VERSION ""

NS_ :

BS_:

BU_: AMS VCU ECU UDV Pit_Tool

BA_DEF_ BO_  "GenMsgCycleTime" INT 0 65535;
BA_DEF_DEF_  "GenMsgCycleTime" 0;

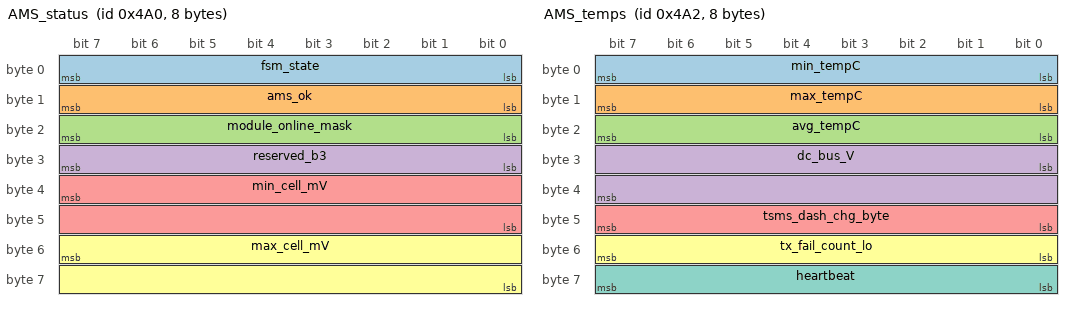
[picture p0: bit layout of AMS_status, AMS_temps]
BO_ 1184 AMS_status: 8 AMS
 SG_ fsm_state : 0|8@1+ (1,0) [0|0] "enum" Vector__XXX
 SG_ ams_ok : 8|8@1+ (1,0) [0|0] "bool" Vector__XXX
 SG_ module_online_mask : 16|8@1+ (1,0) [0|0] "bitmask" Vector__XXX
 SG_ reserved_b3 : 24|8@1+ (1,0) [0|0] "" Vector__XXX
 SG_ min_cell_mV : 39|16@0+ (1,0) [0|0] "mV" Vector__XXX
 SG_ max_cell_mV : 55|16@0+ (1,0) [0|0] "mV" Vector__XXX

BO_ 1185 AMS_pack: 8 AMS
 SG_ pack_voltage_mV : 0|32@1+ (1,0) [0|0] "mV" Vector__XXX
 SG_ filtered_mA : 32|32@1- (1,0) [0|0] "mA" Vector__XXX

BO_ 1186 AMS_temps: 8 AMS
 SG_ min_tempC : 0|8@1- (1,0) [0|0] "degC" Vector__XXX
 SG_ max_tempC : 8|8@1- (1,0) [0|0] "degC" Vector__XXX
 SG_ avg_tempC : 16|8@1- (1,0) [0|0] "degC" Vector__XXX
 SG_ dc_bus_V : 24|16@1+ (1,0) [0|0] "V" Vector__XXX
 SG_ tsms_dash_chg_byte : 40|8@1+ (1,0) [0|0] "bitfield" Vector__XXX
 SG_ tx_fail_count_lo : 48|8@1+ (1,0) [0|0] "" Vector__XXX
 SG_ heartbeat : 56|8@1+ (1,0) [0|0] "" Vector__XXX

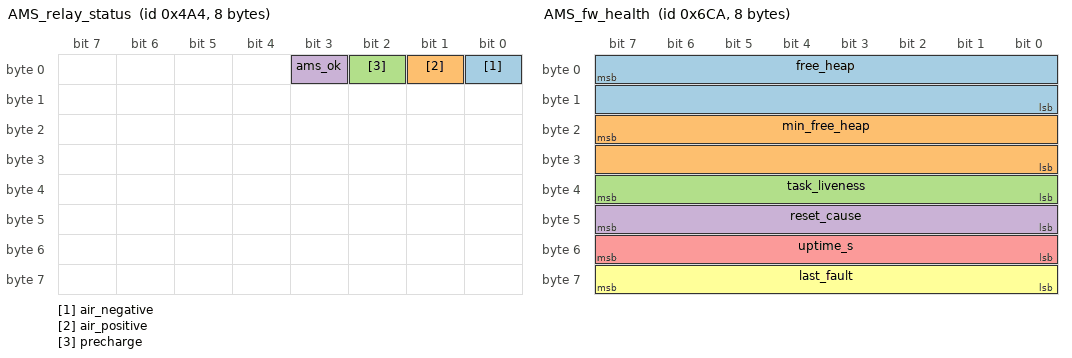
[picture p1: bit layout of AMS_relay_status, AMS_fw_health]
BO_ 1188 AMS_relay_status: 8 AMS
 SG_ air_negative : 0|1@1+ (1,0) [0|0] "bool" Vector__XXX
 SG_ air_positive : 1|1@1+ (1,0) [0|0] "bool" Vector__XXX
 SG_ precharge : 2|1@1+ (1,0) [0|0] "bool" Vector__XXX
 SG_ ams_ok : 3|1@1+ (1,0) [0|0] "bool" Vector__XXX

BO_ 1738 AMS_fw_health: 8 AMS
 SG_ free_heap : 7|16@0+ (1,0) [0|0] "bytes" Vector__XXX
 SG_ min_free_heap : 23|16@0+ (1,0) [0|0] "bytes" Vector__XXX
 SG_ task_liveness : 32|8@1+ (1,0) [0|0] "bitfield" Vector__XXX
 SG_ reset_cause : 40|8@1+ (1,0) [0|0] "enum" Vector__XXX
 SG_ uptime_s : 48|8@1+ (1,0) [0|0] "seconds" Vector__XXX
 SG_ last_fault : 56|8@1+ (1,0) [0|0] "sentinel" Vector__XXX

BO_ 32 ACU_ok_precharge: 1 AMS
 SG_ ok_precharge : 0|8@1+ (1,0) [0|0] "bool" Vector__XXX

BO_ 33 ACU_discharge_interlock: 1 AMS
 SG_ fsm_in_start : 0|1@1+ (1,0) [0|0] "bool" Vector__XXX
 SG_ tsms : 1|1@1+ (1,0) [0|0] "bool" Vector__XXX

BO_ 300 ACU_v_cell_min: 2 AMS
 SG_ min_cell_mV : 7|16@0+ (1,0) [0|0] "mV" Vector__XXX

BO_ 305 ACU_vmin_module_a: 6 AMS
 SG_ vmin_module0 : 7|16@0+ (1,0) [0|0] "mV" Vector__XXX
 SG_ vmin_module1 : 23|16@0+ (1,0) [0|0] "mV" Vector__XXX
 SG_ vmin_module2 : 39|16@0+ (1,0) [0|0] "mV" Vector__XXX

BO_ 306 ACU_vmin_module_b: 4 AMS
 SG_ vmin_module3 : 7|16@0+ (1,0) [0|0] "mV" Vector__XXX
 SG_ vmin_module4 : 23|16@0+ (1,0) [0|0] "mV" Vector__XXX

BO_ 307 ACU_vmax_module_a: 6 AMS
 SG_ vmax_module0 : 7|16@0+ (1,0) [0|0] "mV" Vector__XXX
 SG_ vmax_module1 : 23|16@0+ (1,0) [0|0] "mV" Vector__XXX
 SG_ vmax_module2 : 39|16@0+ (1,0) [0|0] "mV" Vector__XXX

BO_ 308 ACU_vmax_module_b: 4 AMS
 SG_ vmax_module3 : 7|16@0+ (1,0) [0|0] "mV" Vector__XXX
 SG_ vmax_module4 : 23|16@0+ (1,0) [0|0] "mV" Vector__XXX

BO_ 309 ACU_currents: 4 AMS
 SG_ current_accu_dA : 7|16@0- (0.1,0) [0|0] "A" Vector__XXX
 SG_ current_dcdc_dA : 23|16@0- (0.1,0) [0|0] "A" Vector__XXX

BO_ 310 ACU_tmax_module_a: 6 AMS
 SG_ tmax_module0 : 7|16@0- (1,0) [0|0] "degC" Vector__XXX
 SG_ tmax_module1 : 23|16@0- (1,0) [0|0] "degC" Vector__XXX
 SG_ tmax_module2 : 39|16@0- (1,0) [0|0] "degC" Vector__XXX

BO_ 311 ACU_tmax_module_b: 6 AMS
 SG_ tmax_module3 : 7|16@0- (1,0) [0|0] "degC" Vector__XXX
 SG_ tmax_module4 : 23|16@0- (1,0) [0|0] "degC" Vector__XXX
 SG_ tmax_dcdc : 39|16@0- (1,0) [0|0] "degC" Vector__XXX

BO_ 304 ACU_soc: 1 AMS
 SG_ soc_percent : 7|8@0+ (1,0) [0|0] "%" Vector__XXX

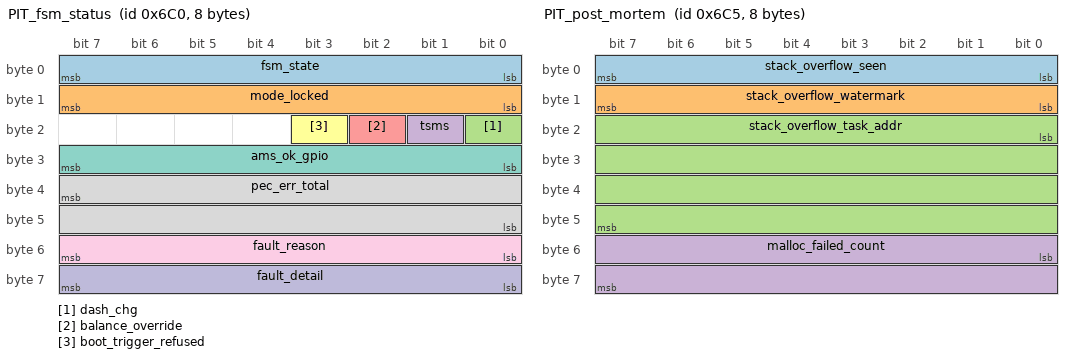
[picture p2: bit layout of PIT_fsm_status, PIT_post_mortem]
BO_ 1728 PIT_fsm_status: 8 AMS
 SG_ fsm_state : 0|8@1+ (1,0) [0|0] "enum" Vector__XXX
 SG_ mode_locked : 8|8@1+ (1,0) [0|0] "enum" Vector__XXX
 SG_ dash_chg : 16|1@1+ (1,0) [0|0] "bool" Vector__XXX
 SG_ tsms : 17|1@1+ (1,0) [0|0] "bool" Vector__XXX
 SG_ balance_override : 18|1@1+ (1,0) [0|0] "bool" Vector__XXX
 SG_ boot_trigger_refused : 19|1@1+ (1,0) [0|0] "bool" Vector__XXX
 SG_ ams_ok_gpio : 24|8@1+ (1,0) [0|0] "bool" Vector__XXX
 SG_ pec_err_total : 39|16@0+ (1,0) [0|0] "count" Vector__XXX
 SG_ fault_reason : 48|8@1+ (1,0) [0|0] "enum" Vector__XXX
 SG_ fault_detail : 56|8@1+ (1,0) [0|0] "" Vector__XXX

BO_ 1729 PIT_timing: 8 AMS
 SG_ bms_volt_poll_ms : 7|16@0+ (1,0) [0|0] "ms" Vector__XXX
 SG_ bms_volt_poll_max_ms : 23|16@0+ (1,0) [0|0] "ms" Vector__XXX
 SG_ temp_sweep_last_mask : 32|32@1+ (1,0) [0|0] "bitmask" Vector__XXX

BO_ 1730 PIT_balance_mask_a: 8 AMS
 SG_ dcc_mask_lo : 0|64@1+ (1,0) [0|0] "bitmask" Vector__XXX

BO_ 1731 PIT_balance_mask_b: 8 AMS
 SG_ dcc_mask_hi : 0|32@1+ (1,0) [0|0] "bitmask" Vector__XXX
 SG_ cycles_total : 32|16@1+ (1,0) [0|0] "count" Vector__XXX
 SG_ cycles_active : 48|16@1+ (1,0) [0|0] "count" Vector__XXX

BO_ 1732 PIT_boot_diag: 8 AMS
 SG_ jump_reason : 0|32@1+ (1,0) [0|0] "enum" Vector__XXX
 SG_ app_init_progress : 32|8@1+ (1,0) [0|0] "count" Vector__XXX
 SG_ fdcan1_start_result : 40|24@1+ (1,0) [0|0] "status" Vector__XXX

BO_ 1733 PIT_post_mortem: 8 AMS
 SG_ stack_overflow_seen : 0|8@1+ (1,0) [0|0] "bool" Vector__XXX
 SG_ stack_overflow_watermark : 8|8@1+ (1,0) [0|0] "" Vector__XXX
 SG_ stack_overflow_task_addr : 16|32@1+ (1,0) [0|0] "" Vector__XXX
 SG_ malloc_failed_count : 48|16@1+ (1,0) [0|0] "count" Vector__XXX

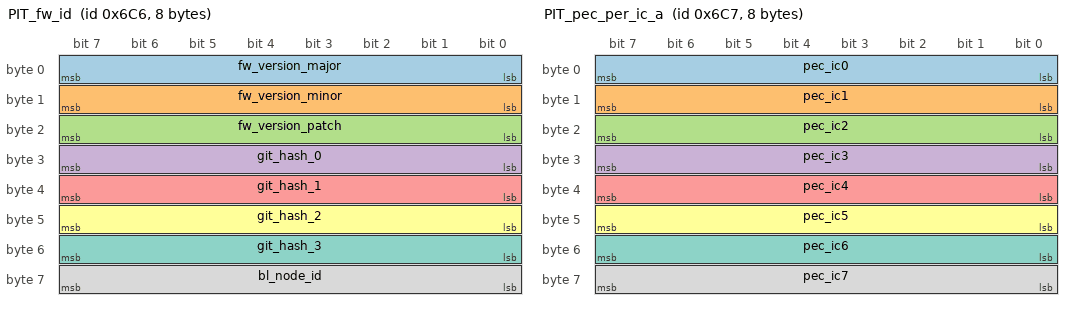
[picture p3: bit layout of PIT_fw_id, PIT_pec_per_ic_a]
BO_ 1734 PIT_fw_id: 8 AMS
 SG_ fw_version_major : 0|8@1+ (1,0) [0|0] "" Vector__XXX
 SG_ fw_version_minor : 8|8@1+ (1,0) [0|0] "" Vector__XXX
 SG_ fw_version_patch : 16|8@1+ (1,0) [0|0] "" Vector__XXX
 SG_ git_hash_0 : 24|8@1+ (1,0) [0|0] "" Vector__XXX
 SG_ git_hash_1 : 32|8@1+ (1,0) [0|0] "" Vector__XXX
 SG_ git_hash_2 : 40|8@1+ (1,0) [0|0] "" Vector__XXX
 SG_ git_hash_3 : 48|8@1+ (1,0) [0|0] "" Vector__XXX
 SG_ bl_node_id : 56|8@1+ (1,0) [0|0] "" Vector__XXX

BO_ 1735 PIT_pec_per_ic_a: 8 AMS
 SG_ pec_ic0 : 0|8@1+ (1,0) [0|0] "count" Vector__XXX
 SG_ pec_ic1 : 8|8@1+ (1,0) [0|0] "count" Vector__XXX
 SG_ pec_ic2 : 16|8@1+ (1,0) [0|0] "count" Vector__XXX
 SG_ pec_ic3 : 24|8@1+ (1,0) [0|0] "count" Vector__XXX
 SG_ pec_ic4 : 32|8@1+ (1,0) [0|0] "count" Vector__XXX
 SG_ pec_ic5 : 40|8@1+ (1,0) [0|0] "count" Vector__XXX
 SG_ pec_ic6 : 48|8@1+ (1,0) [0|0] "count" Vector__XXX
 SG_ pec_ic7 : 56|8@1+ (1,0) [0|0] "count" Vector__XXX

BO_ 1736 PIT_pec_per_ic_b: 8 AMS
 SG_ pec_ic8 : 0|8@1+ (1,0) [0|0] "count" Vector__XXX
 SG_ pec_ic9 : 8|8@1+ (1,0) [0|0] "count" Vector__XXX

BO_ 1737 PIT_comms_health: 8 AMS
 SG_ fdcan1_busoff_recovery_count : 0|32@1+ (1,0) [0|0] "count" Vector__XXX
 SG_ acu_tx_fail : 32|32@1+ (1,0) [0|0] "count" Vector__XXX

BO_ 1739 PIT_balance_health: 8 AMS
 SG_ balance_quiesce_ok : 0|32@1+ (1,0) [0|0] "count" Vector__XXX
 SG_ balance_quiesce_fail : 32|32@1+ (1,0) [0|0] "count" Vector__XXX

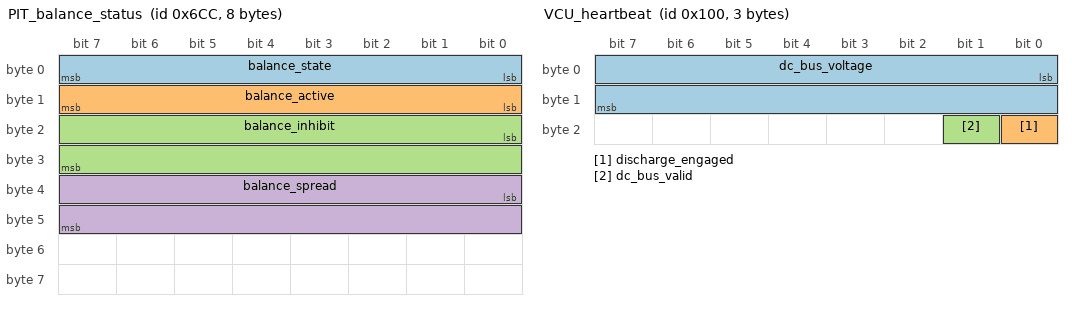
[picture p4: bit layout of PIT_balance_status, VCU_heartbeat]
BO_ 1740 PIT_balance_status: 8 AMS
 SG_ balance_state : 0|8@1+ (1,0) [0|0] "enum" Vector__XXX
 SG_ balance_active : 8|8@1+ (1,0) [0|0] "count" Vector__XXX
 SG_ balance_inhibit : 16|16@1+ (1,0) [0|0] "bitmask" Vector__XXX
 SG_ balance_spread : 32|16@1+ (1,0) [0|0] "mV" Vector__XXX

BO_ 2033 PitDiag_ack: 1 AMS
 SG_ enabled : 0|8@1+ (1,0) [0|0] "bool" Vector__XXX

BO_ 256 VCU_heartbeat: 3 VCU
 SG_ dc_bus_voltage : 0|16@1+ (1,0) [0|0] "V" Vector__XXX
 SG_ discharge_engaged : 16|1@1+ (1,0) [0|0] "bool" Vector__XXX
 SG_ dc_bus_valid : 17|1@1+ (1,0) [0|0] "bool" Vector__XXX

BO_ 257 Operator_charge_request: 4 Pit_Tool
 SG_ magic : 7|32@0+ (1,0) [0|0] "magic" Vector__XXX

BO_ 259 Operator_balance_override: 4 Pit_Tool
 SG_ magic : 7|32@0+ (1,0) [0|0] "magic" Vector__XXX

BO_ 260 Operator_balance_modules: 5 Pit_Tool
 SG_ magic : 7|32@0+ (1,0) [0|0] "magic" Vector__XXX
 SG_ module_enable : 32|5@1+ (1,0) [0|0] "bitmask" Vector__XXX

BO_ 2032 PitDiag_cmd: 4 Pit_Tool
 SG_ cmd_magic : 7|32@0+ (1,0) [0|0] "magic" Vector__XXX

BO_ 2 BL_boot_trigger: 4 Pit_Tool
 SG_ magic : 7|32@0+ (1,0) [0|0] "magic" Vector__XXX

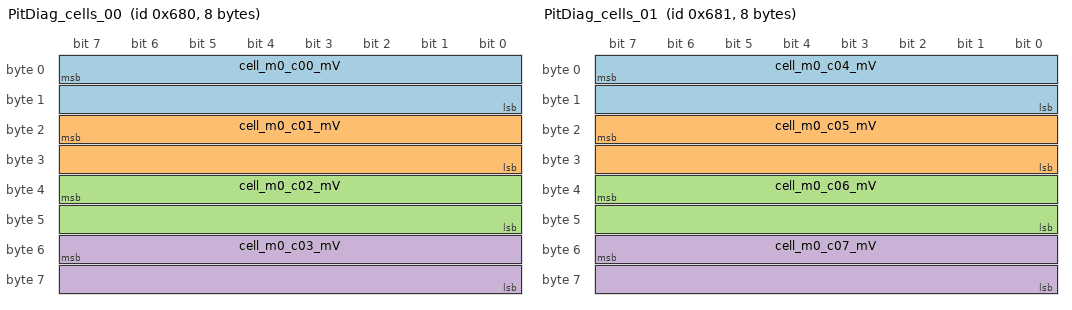
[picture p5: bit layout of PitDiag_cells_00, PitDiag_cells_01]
BO_ 1664 PitDiag_cells_00: 8 AMS
 SG_ cell_m0_c00_mV : 7|16@0+ (1,0) [0|5000] "mV" Vector__XXX
 SG_ cell_m0_c01_mV : 23|16@0+ (1,0) [0|5000] "mV" Vector__XXX
 SG_ cell_m0_c02_mV : 39|16@0+ (1,0) [0|5000] "mV" Vector__XXX
 SG_ cell_m0_c03_mV : 55|16@0+ (1,0) [0|5000] "mV" Vector__XXX

BO_ 1665 PitDiag_cells_01: 8 AMS
 SG_ cell_m0_c04_mV : 7|16@0+ (1,0) [0|5000] "mV" Vector__XXX
 SG_ cell_m0_c05_mV : 23|16@0+ (1,0) [0|5000] "mV" Vector__XXX
 SG_ cell_m0_c06_mV : 39|16@0+ (1,0) [0|5000] "mV" Vector__XXX
 SG_ cell_m0_c07_mV : 55|16@0+ (1,0) [0|5000] "mV" Vector__XXX

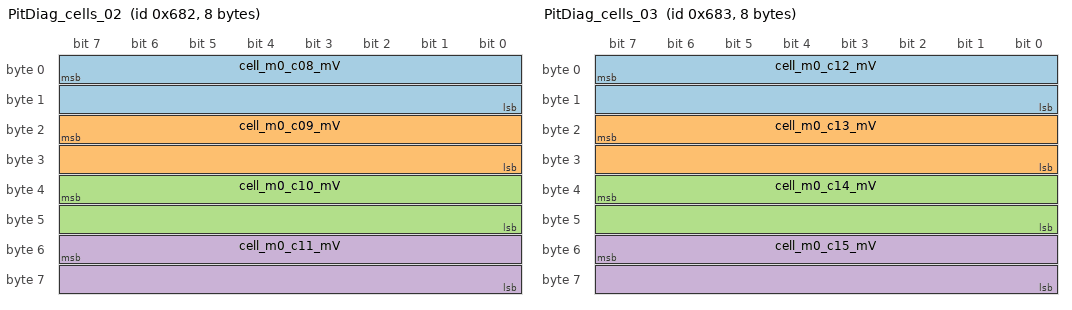
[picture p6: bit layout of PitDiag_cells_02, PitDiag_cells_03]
BO_ 1666 PitDiag_cells_02: 8 AMS
 SG_ cell_m0_c08_mV : 7|16@0+ (1,0) [0|5000] "mV" Vector__XXX
 SG_ cell_m0_c09_mV : 23|16@0+ (1,0) [0|5000] "mV" Vector__XXX
 SG_ cell_m0_c10_mV : 39|16@0+ (1,0) [0|5000] "mV" Vector__XXX
 SG_ cell_m0_c11_mV : 55|16@0+ (1,0) [0|5000] "mV" Vector__XXX

BO_ 1667 PitDiag_cells_03: 8 AMS
 SG_ cell_m0_c12_mV : 7|16@0+ (1,0) [0|5000] "mV" Vector__XXX
 SG_ cell_m0_c13_mV : 23|16@0+ (1,0) [0|5000] "mV" Vector__XXX
 SG_ cell_m0_c14_mV : 39|16@0+ (1,0) [0|5000] "mV" Vector__XXX
 SG_ cell_m0_c15_mV : 55|16@0+ (1,0) [0|5000] "mV" Vector__XXX

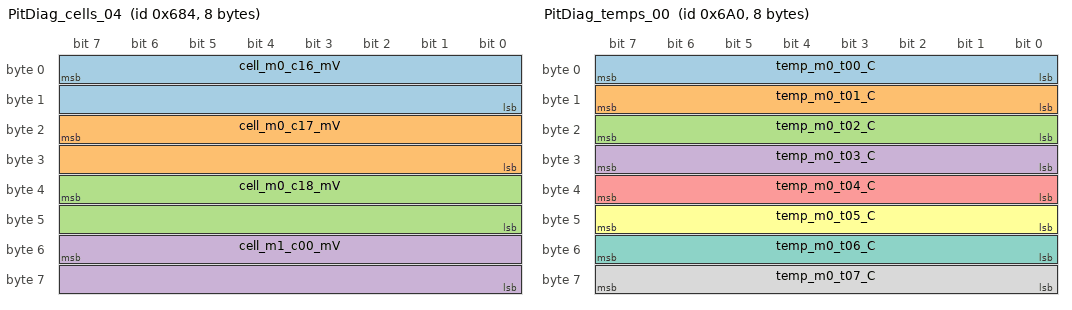
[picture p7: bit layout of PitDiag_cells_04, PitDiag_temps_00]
BO_ 1668 PitDiag_cells_04: 8 AMS
 SG_ cell_m0_c16_mV : 7|16@0+ (1,0) [0|5000] "mV" Vector__XXX
 SG_ cell_m0_c17_mV : 23|16@0+ (1,0) [0|5000] "mV" Vector__XXX
 SG_ cell_m0_c18_mV : 39|16@0+ (1,0) [0|5000] "mV" Vector__XXX
 SG_ cell_m1_c00_mV : 55|16@0+ (1,0) [0|5000] "mV" Vector__XXX

BO_ 1669 PitDiag_cells_05: 8 AMS
 SG_ cell_m1_c01_mV : 7|16@0+ (1,0) [0|5000] "mV" Vector__XXX
 SG_ cell_m1_c02_mV : 23|16@0+ (1,0) [0|5000] "mV" Vector__XXX
 SG_ cell_m1_c03_mV : 39|16@0+ (1,0) [0|5000] "mV" Vector__XXX
 SG_ cell_m1_c04_mV : 55|16@0+ (1,0) [0|5000] "mV" Vector__XXX

BO_ 1670 PitDiag_cells_06: 8 AMS
 SG_ cell_m1_c05_mV : 7|16@0+ (1,0) [0|5000] "mV" Vector__XXX
 SG_ cell_m1_c06_mV : 23|16@0+ (1,0) [0|5000] "mV" Vector__XXX
 SG_ cell_m1_c07_mV : 39|16@0+ (1,0) [0|5000] "mV" Vector__XXX
 SG_ cell_m1_c08_mV : 55|16@0+ (1,0) [0|5000] "mV" Vector__XXX

BO_ 1671 PitDiag_cells_07: 8 AMS
 SG_ cell_m1_c09_mV : 7|16@0+ (1,0) [0|5000] "mV" Vector__XXX
 SG_ cell_m1_c10_mV : 23|16@0+ (1,0) [0|5000] "mV" Vector__XXX
 SG_ cell_m1_c11_mV : 39|16@0+ (1,0) [0|5000] "mV" Vector__XXX
 SG_ cell_m1_c12_mV : 55|16@0+ (1,0) [0|5000] "mV" Vector__XXX

BO_ 1672 PitDiag_cells_08: 8 AMS
 SG_ cell_m1_c13_mV : 7|16@0+ (1,0) [0|5000] "mV" Vector__XXX
 SG_ cell_m1_c14_mV : 23|16@0+ (1,0) [0|5000] "mV" Vector__XXX
 SG_ cell_m1_c15_mV : 39|16@0+ (1,0) [0|5000] "mV" Vector__XXX
 SG_ cell_m1_c16_mV : 55|16@0+ (1,0) [0|5000] "mV" Vector__XXX

BO_ 1673 PitDiag_cells_09: 8 AMS
 SG_ cell_m1_c17_mV : 7|16@0+ (1,0) [0|5000] "mV" Vector__XXX
 SG_ cell_m1_c18_mV : 23|16@0+ (1,0) [0|5000] "mV" Vector__XXX
 SG_ cell_m2_c00_mV : 39|16@0+ (1,0) [0|5000] "mV" Vector__XXX
 SG_ cell_m2_c01_mV : 55|16@0+ (1,0) [0|5000] "mV" Vector__XXX

BO_ 1674 PitDiag_cells_10: 8 AMS
 SG_ cell_m2_c02_mV : 7|16@0+ (1,0) [0|5000] "mV" Vector__XXX
 SG_ cell_m2_c03_mV : 23|16@0+ (1,0) [0|5000] "mV" Vector__XXX
 SG_ cell_m2_c04_mV : 39|16@0+ (1,0) [0|5000] "mV" Vector__XXX
 SG_ cell_m2_c05_mV : 55|16@0+ (1,0) [0|5000] "mV" Vector__XXX

BO_ 1675 PitDiag_cells_11: 8 AMS
 SG_ cell_m2_c06_mV : 7|16@0+ (1,0) [0|5000] "mV" Vector__XXX
 SG_ cell_m2_c07_mV : 23|16@0+ (1,0) [0|5000] "mV" Vector__XXX
 SG_ cell_m2_c08_mV : 39|16@0+ (1,0) [0|5000] "mV" Vector__XXX
 SG_ cell_m2_c09_mV : 55|16@0+ (1,0) [0|5000] "mV" Vector__XXX

BO_ 1676 PitDiag_cells_12: 8 AMS
 SG_ cell_m2_c10_mV : 7|16@0+ (1,0) [0|5000] "mV" Vector__XXX
 SG_ cell_m2_c11_mV : 23|16@0+ (1,0) [0|5000] "mV" Vector__XXX
 SG_ cell_m2_c12_mV : 39|16@0+ (1,0) [0|5000] "mV" Vector__XXX
 SG_ cell_m2_c13_mV : 55|16@0+ (1,0) [0|5000] "mV" Vector__XXX

BO_ 1677 PitDiag_cells_13: 8 AMS
 SG_ cell_m2_c14_mV : 7|16@0+ (1,0) [0|5000] "mV" Vector__XXX
 SG_ cell_m2_c15_mV : 23|16@0+ (1,0) [0|5000] "mV" Vector__XXX
 SG_ cell_m2_c16_mV : 39|16@0+ (1,0) [0|5000] "mV" Vector__XXX
 SG_ cell_m2_c17_mV : 55|16@0+ (1,0) [0|5000] "mV" Vector__XXX

BO_ 1678 PitDiag_cells_14: 8 AMS
 SG_ cell_m2_c18_mV : 7|16@0+ (1,0) [0|5000] "mV" Vector__XXX
 SG_ cell_m3_c00_mV : 23|16@0+ (1,0) [0|5000] "mV" Vector__XXX
 SG_ cell_m3_c01_mV : 39|16@0+ (1,0) [0|5000] "mV" Vector__XXX
 SG_ cell_m3_c02_mV : 55|16@0+ (1,0) [0|5000] "mV" Vector__XXX

BO_ 1679 PitDiag_cells_15: 8 AMS
 SG_ cell_m3_c03_mV : 7|16@0+ (1,0) [0|5000] "mV" Vector__XXX
 SG_ cell_m3_c04_mV : 23|16@0+ (1,0) [0|5000] "mV" Vector__XXX
 SG_ cell_m3_c05_mV : 39|16@0+ (1,0) [0|5000] "mV" Vector__XXX
 SG_ cell_m3_c06_mV : 55|16@0+ (1,0) [0|5000] "mV" Vector__XXX

BO_ 1680 PitDiag_cells_16: 8 AMS
 SG_ cell_m3_c07_mV : 7|16@0+ (1,0) [0|5000] "mV" Vector__XXX
 SG_ cell_m3_c08_mV : 23|16@0+ (1,0) [0|5000] "mV" Vector__XXX
 SG_ cell_m3_c09_mV : 39|16@0+ (1,0) [0|5000] "mV" Vector__XXX
 SG_ cell_m3_c10_mV : 55|16@0+ (1,0) [0|5000] "mV" Vector__XXX

BO_ 1681 PitDiag_cells_17: 8 AMS
 SG_ cell_m3_c11_mV : 7|16@0+ (1,0) [0|5000] "mV" Vector__XXX
 SG_ cell_m3_c12_mV : 23|16@0+ (1,0) [0|5000] "mV" Vector__XXX
 SG_ cell_m3_c13_mV : 39|16@0+ (1,0) [0|5000] "mV" Vector__XXX
 SG_ cell_m3_c14_mV : 55|16@0+ (1,0) [0|5000] "mV" Vector__XXX

BO_ 1682 PitDiag_cells_18: 8 AMS
 SG_ cell_m3_c15_mV : 7|16@0+ (1,0) [0|5000] "mV" Vector__XXX
 SG_ cell_m3_c16_mV : 23|16@0+ (1,0) [0|5000] "mV" Vector__XXX
 SG_ cell_m3_c17_mV : 39|16@0+ (1,0) [0|5000] "mV" Vector__XXX
 SG_ cell_m3_c18_mV : 55|16@0+ (1,0) [0|5000] "mV" Vector__XXX

BO_ 1683 PitDiag_cells_19: 8 AMS
 SG_ cell_m4_c00_mV : 7|16@0+ (1,0) [0|5000] "mV" Vector__XXX
 SG_ cell_m4_c01_mV : 23|16@0+ (1,0) [0|5000] "mV" Vector__XXX
 SG_ cell_m4_c02_mV : 39|16@0+ (1,0) [0|5000] "mV" Vector__XXX
 SG_ cell_m4_c03_mV : 55|16@0+ (1,0) [0|5000] "mV" Vector__XXX

BO_ 1684 PitDiag_cells_20: 8 AMS
 SG_ cell_m4_c04_mV : 7|16@0+ (1,0) [0|5000] "mV" Vector__XXX
 SG_ cell_m4_c05_mV : 23|16@0+ (1,0) [0|5000] "mV" Vector__XXX
 SG_ cell_m4_c06_mV : 39|16@0+ (1,0) [0|5000] "mV" Vector__XXX
 SG_ cell_m4_c07_mV : 55|16@0+ (1,0) [0|5000] "mV" Vector__XXX

BO_ 1685 PitDiag_cells_21: 8 AMS
 SG_ cell_m4_c08_mV : 7|16@0+ (1,0) [0|5000] "mV" Vector__XXX
 SG_ cell_m4_c09_mV : 23|16@0+ (1,0) [0|5000] "mV" Vector__XXX
 SG_ cell_m4_c10_mV : 39|16@0+ (1,0) [0|5000] "mV" Vector__XXX
 SG_ cell_m4_c11_mV : 55|16@0+ (1,0) [0|5000] "mV" Vector__XXX

BO_ 1686 PitDiag_cells_22: 8 AMS
 SG_ cell_m4_c12_mV : 7|16@0+ (1,0) [0|5000] "mV" Vector__XXX
 SG_ cell_m4_c13_mV : 23|16@0+ (1,0) [0|5000] "mV" Vector__XXX
 SG_ cell_m4_c14_mV : 39|16@0+ (1,0) [0|5000] "mV" Vector__XXX
 SG_ cell_m4_c15_mV : 55|16@0+ (1,0) [0|5000] "mV" Vector__XXX

BO_ 1687 PitDiag_cells_23: 8 AMS
 SG_ cell_m4_c16_mV : 7|16@0+ (1,0) [0|5000] "mV" Vector__XXX
 SG_ cell_m4_c17_mV : 23|16@0+ (1,0) [0|5000] "mV" Vector__XXX
 SG_ cell_m4_c18_mV : 39|16@0+ (1,0) [0|5000] "mV" Vector__XXX
 SG_ sentinel_slot3 : 55|16@0+ (1,0) [0|5000] "mV" Vector__XXX

BO_ 1696 PitDiag_temps_00: 8 AMS
 SG_ temp_m0_t00_C : 0|8@1- (1,0) [-128|127] "degC" Vector__XXX
 SG_ temp_m0_t01_C : 8|8@1- (1,0) [-128|127] "degC" Vector__XXX
 SG_ temp_m0_t02_C : 16|8@1- (1,0) [-128|127] "degC" Vector__XXX
 SG_ temp_m0_t03_C : 24|8@1- (1,0) [-128|127] "degC" Vector__XXX
 SG_ temp_m0_t04_C : 32|8@1- (1,0) [-128|127] "degC" Vector__XXX
 SG_ temp_m0_t05_C : 40|8@1- (1,0) [-128|127] "degC" Vector__XXX
 SG_ temp_m0_t06_C : 48|8@1- (1,0) [-128|127] "degC" Vector__XXX
 SG_ temp_m0_t07_C : 56|8@1- (1,0) [-128|127] "degC" Vector__XXX

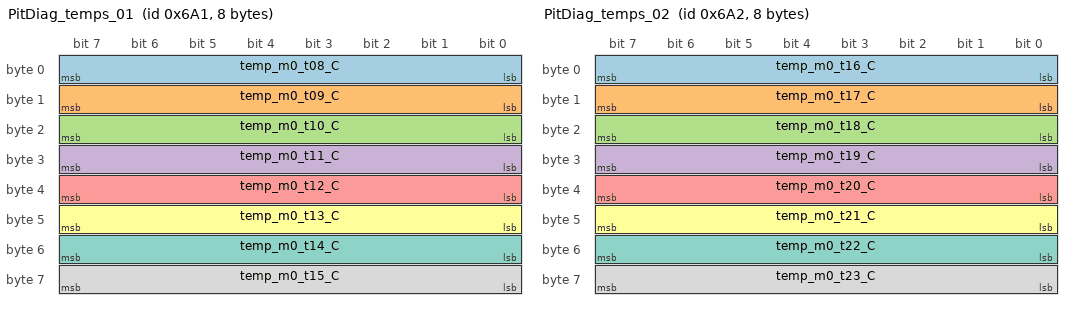
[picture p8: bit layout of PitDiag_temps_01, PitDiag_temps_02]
BO_ 1697 PitDiag_temps_01: 8 AMS
 SG_ temp_m0_t08_C : 0|8@1- (1,0) [-128|127] "degC" Vector__XXX
 SG_ temp_m0_t09_C : 8|8@1- (1,0) [-128|127] "degC" Vector__XXX
 SG_ temp_m0_t10_C : 16|8@1- (1,0) [-128|127] "degC" Vector__XXX
 SG_ temp_m0_t11_C : 24|8@1- (1,0) [-128|127] "degC" Vector__XXX
 SG_ temp_m0_t12_C : 32|8@1- (1,0) [-128|127] "degC" Vector__XXX
 SG_ temp_m0_t13_C : 40|8@1- (1,0) [-128|127] "degC" Vector__XXX
 SG_ temp_m0_t14_C : 48|8@1- (1,0) [-128|127] "degC" Vector__XXX
 SG_ temp_m0_t15_C : 56|8@1- (1,0) [-128|127] "degC" Vector__XXX

BO_ 1698 PitDiag_temps_02: 8 AMS
 SG_ temp_m0_t16_C : 0|8@1- (1,0) [-128|127] "degC" Vector__XXX
 SG_ temp_m0_t17_C : 8|8@1- (1,0) [-128|127] "degC" Vector__XXX
 SG_ temp_m0_t18_C : 16|8@1- (1,0) [-128|127] "degC" Vector__XXX
 SG_ temp_m0_t19_C : 24|8@1- (1,0) [-128|127] "degC" Vector__XXX
 SG_ temp_m0_t20_C : 32|8@1- (1,0) [-128|127] "degC" Vector__XXX
 SG_ temp_m0_t21_C : 40|8@1- (1,0) [-128|127] "degC" Vector__XXX
 SG_ temp_m0_t22_C : 48|8@1- (1,0) [-128|127] "degC" Vector__XXX
 SG_ temp_m0_t23_C : 56|8@1- (1,0) [-128|127] "degC" Vector__XXX

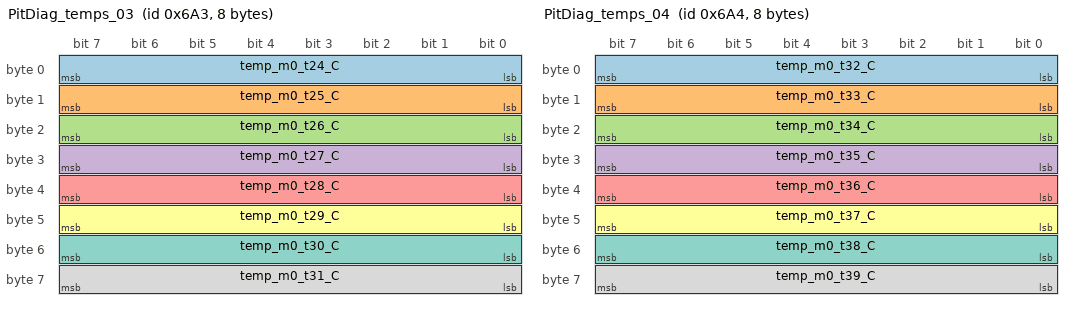
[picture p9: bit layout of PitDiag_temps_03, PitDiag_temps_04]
BO_ 1699 PitDiag_temps_03: 8 AMS
 SG_ temp_m0_t24_C : 0|8@1- (1,0) [-128|127] "degC" Vector__XXX
 SG_ temp_m0_t25_C : 8|8@1- (1,0) [-128|127] "degC" Vector__XXX
 SG_ temp_m0_t26_C : 16|8@1- (1,0) [-128|127] "degC" Vector__XXX
 SG_ temp_m0_t27_C : 24|8@1- (1,0) [-128|127] "degC" Vector__XXX
 SG_ temp_m0_t28_C : 32|8@1- (1,0) [-128|127] "degC" Vector__XXX
 SG_ temp_m0_t29_C : 40|8@1- (1,0) [-128|127] "degC" Vector__XXX
 SG_ temp_m0_t30_C : 48|8@1- (1,0) [-128|127] "degC" Vector__XXX
 SG_ temp_m0_t31_C : 56|8@1- (1,0) [-128|127] "degC" Vector__XXX

BO_ 1700 PitDiag_temps_04: 8 AMS
 SG_ temp_m0_t32_C : 0|8@1- (1,0) [-128|127] "degC" Vector__XXX
 SG_ temp_m0_t33_C : 8|8@1- (1,0) [-128|127] "degC" Vector__XXX
 SG_ temp_m0_t34_C : 16|8@1- (1,0) [-128|127] "degC" Vector__XXX
 SG_ temp_m0_t35_C : 24|8@1- (1,0) [-128|127] "degC" Vector__XXX
 SG_ temp_m0_t36_C : 32|8@1- (1,0) [-128|127] "degC" Vector__XXX
 SG_ temp_m0_t37_C : 40|8@1- (1,0) [-128|127] "degC" Vector__XXX
 SG_ temp_m0_t38_C : 48|8@1- (1,0) [-128|127] "degC" Vector__XXX
 SG_ temp_m0_t39_C : 56|8@1- (1,0) [-128|127] "degC" Vector__XXX

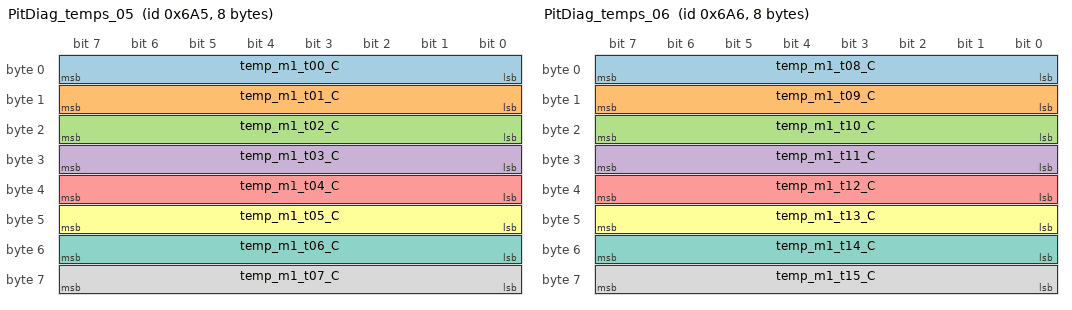
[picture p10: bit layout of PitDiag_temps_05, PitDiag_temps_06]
BO_ 1701 PitDiag_temps_05: 8 AMS
 SG_ temp_m1_t00_C : 0|8@1- (1,0) [-128|127] "degC" Vector__XXX
 SG_ temp_m1_t01_C : 8|8@1- (1,0) [-128|127] "degC" Vector__XXX
 SG_ temp_m1_t02_C : 16|8@1- (1,0) [-128|127] "degC" Vector__XXX
 SG_ temp_m1_t03_C : 24|8@1- (1,0) [-128|127] "degC" Vector__XXX
 SG_ temp_m1_t04_C : 32|8@1- (1,0) [-128|127] "degC" Vector__XXX
 SG_ temp_m1_t05_C : 40|8@1- (1,0) [-128|127] "degC" Vector__XXX
 SG_ temp_m1_t06_C : 48|8@1- (1,0) [-128|127] "degC" Vector__XXX
 SG_ temp_m1_t07_C : 56|8@1- (1,0) [-128|127] "degC" Vector__XXX

BO_ 1702 PitDiag_temps_06: 8 AMS
 SG_ temp_m1_t08_C : 0|8@1- (1,0) [-128|127] "degC" Vector__XXX
 SG_ temp_m1_t09_C : 8|8@1- (1,0) [-128|127] "degC" Vector__XXX
 SG_ temp_m1_t10_C : 16|8@1- (1,0) [-128|127] "degC" Vector__XXX
 SG_ temp_m1_t11_C : 24|8@1- (1,0) [-128|127] "degC" Vector__XXX
 SG_ temp_m1_t12_C : 32|8@1- (1,0) [-128|127] "degC" Vector__XXX
 SG_ temp_m1_t13_C : 40|8@1- (1,0) [-128|127] "degC" Vector__XXX
 SG_ temp_m1_t14_C : 48|8@1- (1,0) [-128|127] "degC" Vector__XXX
 SG_ temp_m1_t15_C : 56|8@1- (1,0) [-128|127] "degC" Vector__XXX

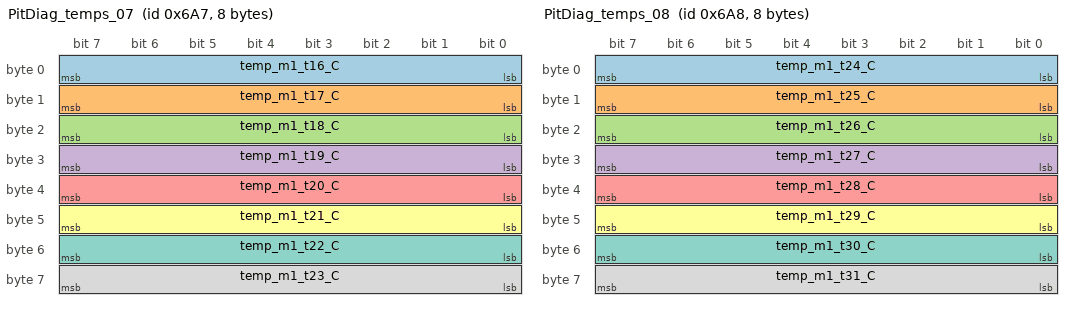
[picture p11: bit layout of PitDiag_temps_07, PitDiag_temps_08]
BO_ 1703 PitDiag_temps_07: 8 AMS
 SG_ temp_m1_t16_C : 0|8@1- (1,0) [-128|127] "degC" Vector__XXX
 SG_ temp_m1_t17_C : 8|8@1- (1,0) [-128|127] "degC" Vector__XXX
 SG_ temp_m1_t18_C : 16|8@1- (1,0) [-128|127] "degC" Vector__XXX
 SG_ temp_m1_t19_C : 24|8@1- (1,0) [-128|127] "degC" Vector__XXX
 SG_ temp_m1_t20_C : 32|8@1- (1,0) [-128|127] "degC" Vector__XXX
 SG_ temp_m1_t21_C : 40|8@1- (1,0) [-128|127] "degC" Vector__XXX
 SG_ temp_m1_t22_C : 48|8@1- (1,0) [-128|127] "degC" Vector__XXX
 SG_ temp_m1_t23_C : 56|8@1- (1,0) [-128|127] "degC" Vector__XXX

BO_ 1704 PitDiag_temps_08: 8 AMS
 SG_ temp_m1_t24_C : 0|8@1- (1,0) [-128|127] "degC" Vector__XXX
 SG_ temp_m1_t25_C : 8|8@1- (1,0) [-128|127] "degC" Vector__XXX
 SG_ temp_m1_t26_C : 16|8@1- (1,0) [-128|127] "degC" Vector__XXX
 SG_ temp_m1_t27_C : 24|8@1- (1,0) [-128|127] "degC" Vector__XXX
 SG_ temp_m1_t28_C : 32|8@1- (1,0) [-128|127] "degC" Vector__XXX
 SG_ temp_m1_t29_C : 40|8@1- (1,0) [-128|127] "degC" Vector__XXX
 SG_ temp_m1_t30_C : 48|8@1- (1,0) [-128|127] "degC" Vector__XXX
 SG_ temp_m1_t31_C : 56|8@1- (1,0) [-128|127] "degC" Vector__XXX

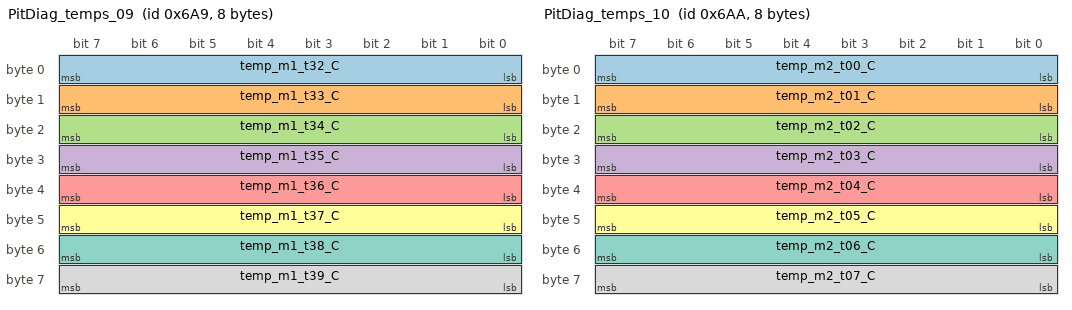
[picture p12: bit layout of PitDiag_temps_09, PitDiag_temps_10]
BO_ 1705 PitDiag_temps_09: 8 AMS
 SG_ temp_m1_t32_C : 0|8@1- (1,0) [-128|127] "degC" Vector__XXX
 SG_ temp_m1_t33_C : 8|8@1- (1,0) [-128|127] "degC" Vector__XXX
 SG_ temp_m1_t34_C : 16|8@1- (1,0) [-128|127] "degC" Vector__XXX
 SG_ temp_m1_t35_C : 24|8@1- (1,0) [-128|127] "degC" Vector__XXX
 SG_ temp_m1_t36_C : 32|8@1- (1,0) [-128|127] "degC" Vector__XXX
 SG_ temp_m1_t37_C : 40|8@1- (1,0) [-128|127] "degC" Vector__XXX
 SG_ temp_m1_t38_C : 48|8@1- (1,0) [-128|127] "degC" Vector__XXX
 SG_ temp_m1_t39_C : 56|8@1- (1,0) [-128|127] "degC" Vector__XXX

BO_ 1706 PitDiag_temps_10: 8 AMS
 SG_ temp_m2_t00_C : 0|8@1- (1,0) [-128|127] "degC" Vector__XXX
 SG_ temp_m2_t01_C : 8|8@1- (1,0) [-128|127] "degC" Vector__XXX
 SG_ temp_m2_t02_C : 16|8@1- (1,0) [-128|127] "degC" Vector__XXX
 SG_ temp_m2_t03_C : 24|8@1- (1,0) [-128|127] "degC" Vector__XXX
 SG_ temp_m2_t04_C : 32|8@1- (1,0) [-128|127] "degC" Vector__XXX
 SG_ temp_m2_t05_C : 40|8@1- (1,0) [-128|127] "degC" Vector__XXX
 SG_ temp_m2_t06_C : 48|8@1- (1,0) [-128|127] "degC" Vector__XXX
 SG_ temp_m2_t07_C : 56|8@1- (1,0) [-128|127] "degC" Vector__XXX

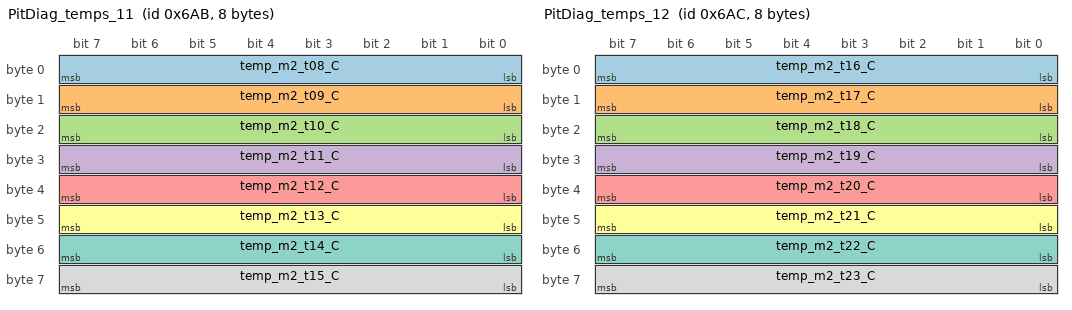
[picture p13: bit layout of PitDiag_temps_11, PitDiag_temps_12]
BO_ 1707 PitDiag_temps_11: 8 AMS
 SG_ temp_m2_t08_C : 0|8@1- (1,0) [-128|127] "degC" Vector__XXX
 SG_ temp_m2_t09_C : 8|8@1- (1,0) [-128|127] "degC" Vector__XXX
 SG_ temp_m2_t10_C : 16|8@1- (1,0) [-128|127] "degC" Vector__XXX
 SG_ temp_m2_t11_C : 24|8@1- (1,0) [-128|127] "degC" Vector__XXX
 SG_ temp_m2_t12_C : 32|8@1- (1,0) [-128|127] "degC" Vector__XXX
 SG_ temp_m2_t13_C : 40|8@1- (1,0) [-128|127] "degC" Vector__XXX
 SG_ temp_m2_t14_C : 48|8@1- (1,0) [-128|127] "degC" Vector__XXX
 SG_ temp_m2_t15_C : 56|8@1- (1,0) [-128|127] "degC" Vector__XXX

BO_ 1708 PitDiag_temps_12: 8 AMS
 SG_ temp_m2_t16_C : 0|8@1- (1,0) [-128|127] "degC" Vector__XXX
 SG_ temp_m2_t17_C : 8|8@1- (1,0) [-128|127] "degC" Vector__XXX
 SG_ temp_m2_t18_C : 16|8@1- (1,0) [-128|127] "degC" Vector__XXX
 SG_ temp_m2_t19_C : 24|8@1- (1,0) [-128|127] "degC" Vector__XXX
 SG_ temp_m2_t20_C : 32|8@1- (1,0) [-128|127] "degC" Vector__XXX
 SG_ temp_m2_t21_C : 40|8@1- (1,0) [-128|127] "degC" Vector__XXX
 SG_ temp_m2_t22_C : 48|8@1- (1,0) [-128|127] "degC" Vector__XXX
 SG_ temp_m2_t23_C : 56|8@1- (1,0) [-128|127] "degC" Vector__XXX

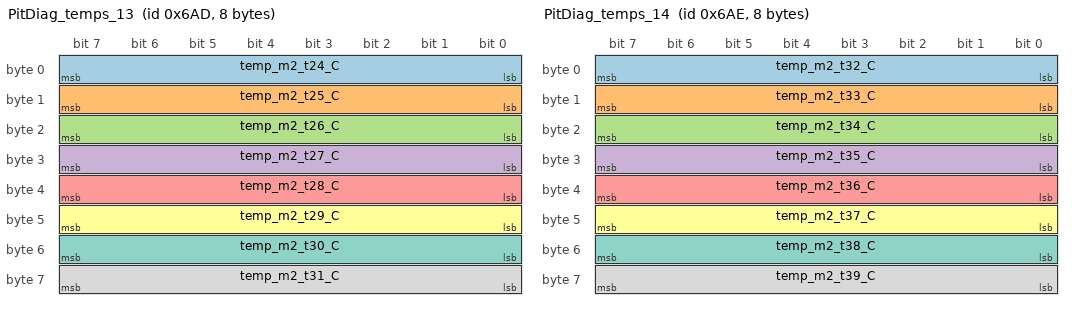
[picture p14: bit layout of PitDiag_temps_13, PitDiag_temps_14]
BO_ 1709 PitDiag_temps_13: 8 AMS
 SG_ temp_m2_t24_C : 0|8@1- (1,0) [-128|127] "degC" Vector__XXX
 SG_ temp_m2_t25_C : 8|8@1- (1,0) [-128|127] "degC" Vector__XXX
 SG_ temp_m2_t26_C : 16|8@1- (1,0) [-128|127] "degC" Vector__XXX
 SG_ temp_m2_t27_C : 24|8@1- (1,0) [-128|127] "degC" Vector__XXX
 SG_ temp_m2_t28_C : 32|8@1- (1,0) [-128|127] "degC" Vector__XXX
 SG_ temp_m2_t29_C : 40|8@1- (1,0) [-128|127] "degC" Vector__XXX
 SG_ temp_m2_t30_C : 48|8@1- (1,0) [-128|127] "degC" Vector__XXX
 SG_ temp_m2_t31_C : 56|8@1- (1,0) [-128|127] "degC" Vector__XXX

BO_ 1710 PitDiag_temps_14: 8 AMS
 SG_ temp_m2_t32_C : 0|8@1- (1,0) [-128|127] "degC" Vector__XXX
 SG_ temp_m2_t33_C : 8|8@1- (1,0) [-128|127] "degC" Vector__XXX
 SG_ temp_m2_t34_C : 16|8@1- (1,0) [-128|127] "degC" Vector__XXX
 SG_ temp_m2_t35_C : 24|8@1- (1,0) [-128|127] "degC" Vector__XXX
 SG_ temp_m2_t36_C : 32|8@1- (1,0) [-128|127] "degC" Vector__XXX
 SG_ temp_m2_t37_C : 40|8@1- (1,0) [-128|127] "degC" Vector__XXX
 SG_ temp_m2_t38_C : 48|8@1- (1,0) [-128|127] "degC" Vector__XXX
 SG_ temp_m2_t39_C : 56|8@1- (1,0) [-128|127] "degC" Vector__XXX

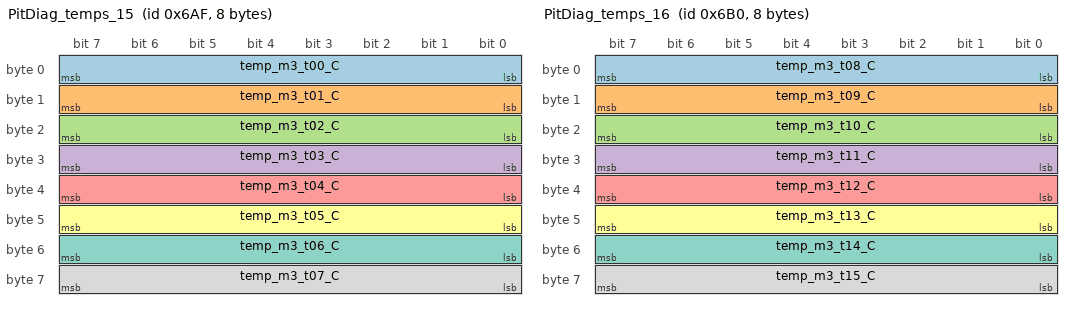
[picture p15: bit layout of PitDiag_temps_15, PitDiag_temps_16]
BO_ 1711 PitDiag_temps_15: 8 AMS
 SG_ temp_m3_t00_C : 0|8@1- (1,0) [-128|127] "degC" Vector__XXX
 SG_ temp_m3_t01_C : 8|8@1- (1,0) [-128|127] "degC" Vector__XXX
 SG_ temp_m3_t02_C : 16|8@1- (1,0) [-128|127] "degC" Vector__XXX
 SG_ temp_m3_t03_C : 24|8@1- (1,0) [-128|127] "degC" Vector__XXX
 SG_ temp_m3_t04_C : 32|8@1- (1,0) [-128|127] "degC" Vector__XXX
 SG_ temp_m3_t05_C : 40|8@1- (1,0) [-128|127] "degC" Vector__XXX
 SG_ temp_m3_t06_C : 48|8@1- (1,0) [-128|127] "degC" Vector__XXX
 SG_ temp_m3_t07_C : 56|8@1- (1,0) [-128|127] "degC" Vector__XXX

BO_ 1712 PitDiag_temps_16: 8 AMS
 SG_ temp_m3_t08_C : 0|8@1- (1,0) [-128|127] "degC" Vector__XXX
 SG_ temp_m3_t09_C : 8|8@1- (1,0) [-128|127] "degC" Vector__XXX
 SG_ temp_m3_t10_C : 16|8@1- (1,0) [-128|127] "degC" Vector__XXX
 SG_ temp_m3_t11_C : 24|8@1- (1,0) [-128|127] "degC" Vector__XXX
 SG_ temp_m3_t12_C : 32|8@1- (1,0) [-128|127] "degC" Vector__XXX
 SG_ temp_m3_t13_C : 40|8@1- (1,0) [-128|127] "degC" Vector__XXX
 SG_ temp_m3_t14_C : 48|8@1- (1,0) [-128|127] "degC" Vector__XXX
 SG_ temp_m3_t15_C : 56|8@1- (1,0) [-128|127] "degC" Vector__XXX

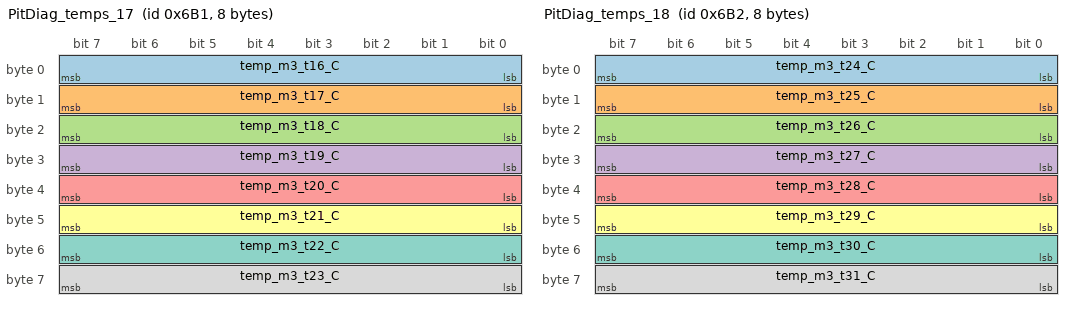
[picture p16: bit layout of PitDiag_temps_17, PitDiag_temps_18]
BO_ 1713 PitDiag_temps_17: 8 AMS
 SG_ temp_m3_t16_C : 0|8@1- (1,0) [-128|127] "degC" Vector__XXX
 SG_ temp_m3_t17_C : 8|8@1- (1,0) [-128|127] "degC" Vector__XXX
 SG_ temp_m3_t18_C : 16|8@1- (1,0) [-128|127] "degC" Vector__XXX
 SG_ temp_m3_t19_C : 24|8@1- (1,0) [-128|127] "degC" Vector__XXX
 SG_ temp_m3_t20_C : 32|8@1- (1,0) [-128|127] "degC" Vector__XXX
 SG_ temp_m3_t21_C : 40|8@1- (1,0) [-128|127] "degC" Vector__XXX
 SG_ temp_m3_t22_C : 48|8@1- (1,0) [-128|127] "degC" Vector__XXX
 SG_ temp_m3_t23_C : 56|8@1- (1,0) [-128|127] "degC" Vector__XXX

BO_ 1714 PitDiag_temps_18: 8 AMS
 SG_ temp_m3_t24_C : 0|8@1- (1,0) [-128|127] "degC" Vector__XXX
 SG_ temp_m3_t25_C : 8|8@1- (1,0) [-128|127] "degC" Vector__XXX
 SG_ temp_m3_t26_C : 16|8@1- (1,0) [-128|127] "degC" Vector__XXX
 SG_ temp_m3_t27_C : 24|8@1- (1,0) [-128|127] "degC" Vector__XXX
 SG_ temp_m3_t28_C : 32|8@1- (1,0) [-128|127] "degC" Vector__XXX
 SG_ temp_m3_t29_C : 40|8@1- (1,0) [-128|127] "degC" Vector__XXX
 SG_ temp_m3_t30_C : 48|8@1- (1,0) [-128|127] "degC" Vector__XXX
 SG_ temp_m3_t31_C : 56|8@1- (1,0) [-128|127] "degC" Vector__XXX

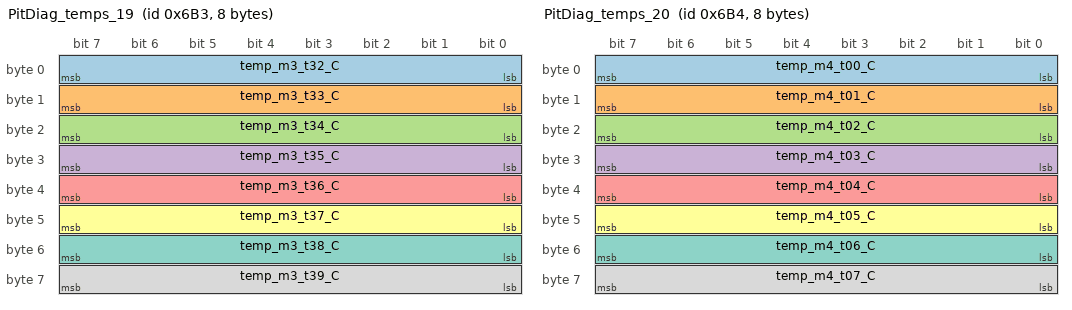
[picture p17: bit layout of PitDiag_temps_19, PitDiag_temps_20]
BO_ 1715 PitDiag_temps_19: 8 AMS
 SG_ temp_m3_t32_C : 0|8@1- (1,0) [-128|127] "degC" Vector__XXX
 SG_ temp_m3_t33_C : 8|8@1- (1,0) [-128|127] "degC" Vector__XXX
 SG_ temp_m3_t34_C : 16|8@1- (1,0) [-128|127] "degC" Vector__XXX
 SG_ temp_m3_t35_C : 24|8@1- (1,0) [-128|127] "degC" Vector__XXX
 SG_ temp_m3_t36_C : 32|8@1- (1,0) [-128|127] "degC" Vector__XXX
 SG_ temp_m3_t37_C : 40|8@1- (1,0) [-128|127] "degC" Vector__XXX
 SG_ temp_m3_t38_C : 48|8@1- (1,0) [-128|127] "degC" Vector__XXX
 SG_ temp_m3_t39_C : 56|8@1- (1,0) [-128|127] "degC" Vector__XXX

BO_ 1716 PitDiag_temps_20: 8 AMS
 SG_ temp_m4_t00_C : 0|8@1- (1,0) [-128|127] "degC" Vector__XXX
 SG_ temp_m4_t01_C : 8|8@1- (1,0) [-128|127] "degC" Vector__XXX
 SG_ temp_m4_t02_C : 16|8@1- (1,0) [-128|127] "degC" Vector__XXX
 SG_ temp_m4_t03_C : 24|8@1- (1,0) [-128|127] "degC" Vector__XXX
 SG_ temp_m4_t04_C : 32|8@1- (1,0) [-128|127] "degC" Vector__XXX
 SG_ temp_m4_t05_C : 40|8@1- (1,0) [-128|127] "degC" Vector__XXX
 SG_ temp_m4_t06_C : 48|8@1- (1,0) [-128|127] "degC" Vector__XXX
 SG_ temp_m4_t07_C : 56|8@1- (1,0) [-128|127] "degC" Vector__XXX

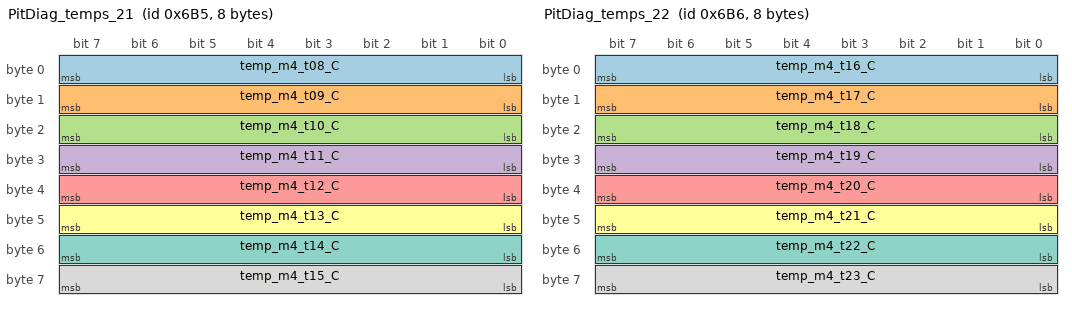
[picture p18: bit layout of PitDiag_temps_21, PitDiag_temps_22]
BO_ 1717 PitDiag_temps_21: 8 AMS
 SG_ temp_m4_t08_C : 0|8@1- (1,0) [-128|127] "degC" Vector__XXX
 SG_ temp_m4_t09_C : 8|8@1- (1,0) [-128|127] "degC" Vector__XXX
 SG_ temp_m4_t10_C : 16|8@1- (1,0) [-128|127] "degC" Vector__XXX
 SG_ temp_m4_t11_C : 24|8@1- (1,0) [-128|127] "degC" Vector__XXX
 SG_ temp_m4_t12_C : 32|8@1- (1,0) [-128|127] "degC" Vector__XXX
 SG_ temp_m4_t13_C : 40|8@1- (1,0) [-128|127] "degC" Vector__XXX
 SG_ temp_m4_t14_C : 48|8@1- (1,0) [-128|127] "degC" Vector__XXX
 SG_ temp_m4_t15_C : 56|8@1- (1,0) [-128|127] "degC" Vector__XXX

BO_ 1718 PitDiag_temps_22: 8 AMS
 SG_ temp_m4_t16_C : 0|8@1- (1,0) [-128|127] "degC" Vector__XXX
 SG_ temp_m4_t17_C : 8|8@1- (1,0) [-128|127] "degC" Vector__XXX
 SG_ temp_m4_t18_C : 16|8@1- (1,0) [-128|127] "degC" Vector__XXX
 SG_ temp_m4_t19_C : 24|8@1- (1,0) [-128|127] "degC" Vector__XXX
 SG_ temp_m4_t20_C : 32|8@1- (1,0) [-128|127] "degC" Vector__XXX
 SG_ temp_m4_t21_C : 40|8@1- (1,0) [-128|127] "degC" Vector__XXX
 SG_ temp_m4_t22_C : 48|8@1- (1,0) [-128|127] "degC" Vector__XXX
 SG_ temp_m4_t23_C : 56|8@1- (1,0) [-128|127] "degC" Vector__XXX

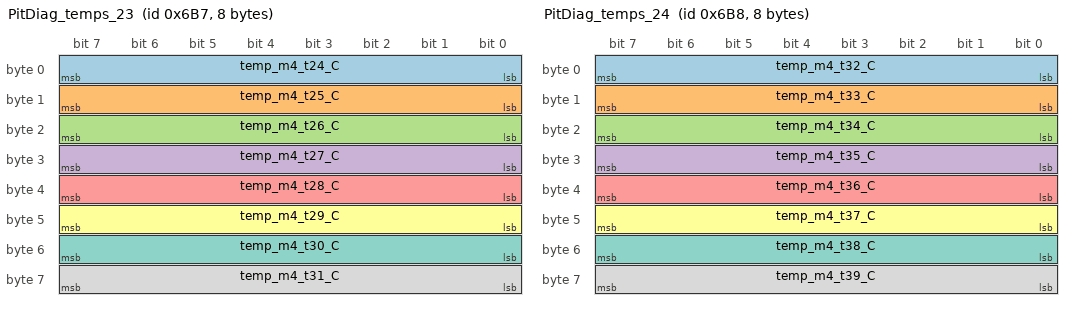
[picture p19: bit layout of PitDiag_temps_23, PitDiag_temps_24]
BO_ 1719 PitDiag_temps_23: 8 AMS
 SG_ temp_m4_t24_C : 0|8@1- (1,0) [-128|127] "degC" Vector__XXX
 SG_ temp_m4_t25_C : 8|8@1- (1,0) [-128|127] "degC" Vector__XXX
 SG_ temp_m4_t26_C : 16|8@1- (1,0) [-128|127] "degC" Vector__XXX
 SG_ temp_m4_t27_C : 24|8@1- (1,0) [-128|127] "degC" Vector__XXX
 SG_ temp_m4_t28_C : 32|8@1- (1,0) [-128|127] "degC" Vector__XXX
 SG_ temp_m4_t29_C : 40|8@1- (1,0) [-128|127] "degC" Vector__XXX
 SG_ temp_m4_t30_C : 48|8@1- (1,0) [-128|127] "degC" Vector__XXX
 SG_ temp_m4_t31_C : 56|8@1- (1,0) [-128|127] "degC" Vector__XXX

BO_ 1720 PitDiag_temps_24: 8 AMS
 SG_ temp_m4_t32_C : 0|8@1- (1,0) [-128|127] "degC" Vector__XXX
 SG_ temp_m4_t33_C : 8|8@1- (1,0) [-128|127] "degC" Vector__XXX
 SG_ temp_m4_t34_C : 16|8@1- (1,0) [-128|127] "degC" Vector__XXX
 SG_ temp_m4_t35_C : 24|8@1- (1,0) [-128|127] "degC" Vector__XXX
 SG_ temp_m4_t36_C : 32|8@1- (1,0) [-128|127] "degC" Vector__XXX
 SG_ temp_m4_t37_C : 40|8@1- (1,0) [-128|127] "degC" Vector__XXX
 SG_ temp_m4_t38_C : 48|8@1- (1,0) [-128|127] "degC" Vector__XXX
 SG_ temp_m4_t39_C : 56|8@1- (1,0) [-128|127] "degC" Vector__XXX

BA_ "GenMsgCycleTime" BO_ 1184 500;
BA_ "GenMsgCycleTime" BO_ 1185 500;
BA_ "GenMsgCycleTime" BO_ 1186 500;
BA_ "GenMsgCycleTime" BO_ 1188 100;
BA_ "GenMsgCycleTime" BO_ 1738 1000;
BA_ "GenMsgCycleTime" BO_ 32 100;
BA_ "GenMsgCycleTime" BO_ 33 100;
BA_ "GenMsgCycleTime" BO_ 300 100;
BA_ "GenMsgCycleTime" BO_ 305 100;
BA_ "GenMsgCycleTime" BO_ 306 100;
BA_ "GenMsgCycleTime" BO_ 307 100;
BA_ "GenMsgCycleTime" BO_ 308 100;
BA_ "GenMsgCycleTime" BO_ 309 50;
BA_ "GenMsgCycleTime" BO_ 310 250;
BA_ "GenMsgCycleTime" BO_ 311 250;
BA_ "GenMsgCycleTime" BO_ 304 250;
BA_ "GenMsgCycleTime" BO_ 1728 1000;
BA_ "GenMsgCycleTime" BO_ 1729 1000;
BA_ "GenMsgCycleTime" BO_ 1730 1000;
BA_ "GenMsgCycleTime" BO_ 1731 1000;
BA_ "GenMsgCycleTime" BO_ 1732 1000;
BA_ "GenMsgCycleTime" BO_ 1733 1000;
BA_ "GenMsgCycleTime" BO_ 1734 1000;
BA_ "GenMsgCycleTime" BO_ 1735 1000;
BA_ "GenMsgCycleTime" BO_ 1736 1000;
BA_ "GenMsgCycleTime" BO_ 1737 1000;
BA_ "GenMsgCycleTime" BO_ 1739 1000;
BA_ "GenMsgCycleTime" BO_ 1740 1000;
BA_ "GenMsgCycleTime" BO_ 256 10;
BA_ "GenMsgCycleTime" BO_ 1664 1000;
BA_ "GenMsgCycleTime" BO_ 1665 1000;
BA_ "GenMsgCycleTime" BO_ 1666 1000;
BA_ "GenMsgCycleTime" BO_ 1667 1000;
BA_ "GenMsgCycleTime" BO_ 1668 1000;
BA_ "GenMsgCycleTime" BO_ 1669 1000;
BA_ "GenMsgCycleTime" BO_ 1670 1000;
BA_ "GenMsgCycleTime" BO_ 1671 1000;
BA_ "GenMsgCycleTime" BO_ 1672 1000;
BA_ "GenMsgCycleTime" BO_ 1673 1000;
BA_ "GenMsgCycleTime" BO_ 1674 1000;
BA_ "GenMsgCycleTime" BO_ 1675 1000;
BA_ "GenMsgCycleTime" BO_ 1676 1000;
BA_ "GenMsgCycleTime" BO_ 1677 1000;
BA_ "GenMsgCycleTime" BO_ 1678 1000;
BA_ "GenMsgCycleTime" BO_ 1679 1000;
BA_ "GenMsgCycleTime" BO_ 1680 1000;
BA_ "GenMsgCycleTime" BO_ 1681 1000;
BA_ "GenMsgCycleTime" BO_ 1682 1000;
BA_ "GenMsgCycleTime" BO_ 1683 1000;
BA_ "GenMsgCycleTime" BO_ 1684 1000;
BA_ "GenMsgCycleTime" BO_ 1685 1000;
BA_ "GenMsgCycleTime" BO_ 1686 1000;
BA_ "GenMsgCycleTime" BO_ 1687 1000;
BA_ "GenMsgCycleTime" BO_ 1696 1000;
BA_ "GenMsgCycleTime" BO_ 1697 1000;
BA_ "GenMsgCycleTime" BO_ 1698 1000;
BA_ "GenMsgCycleTime" BO_ 1699 1000;
BA_ "GenMsgCycleTime" BO_ 1700 1000;
BA_ "GenMsgCycleTime" BO_ 1701 1000;
BA_ "GenMsgCycleTime" BO_ 1702 1000;
BA_ "GenMsgCycleTime" BO_ 1703 1000;
BA_ "GenMsgCycleTime" BO_ 1704 1000;
BA_ "GenMsgCycleTime" BO_ 1705 1000;
BA_ "GenMsgCycleTime" BO_ 1706 1000;
BA_ "GenMsgCycleTime" BO_ 1707 1000;
BA_ "GenMsgCycleTime" BO_ 1708 1000;
BA_ "GenMsgCycleTime" BO_ 1709 1000;
BA_ "GenMsgCycleTime" BO_ 1710 1000;
BA_ "GenMsgCycleTime" BO_ 1711 1000;
BA_ "GenMsgCycleTime" BO_ 1712 1000;
BA_ "GenMsgCycleTime" BO_ 1713 1000;
BA_ "GenMsgCycleTime" BO_ 1714 1000;
BA_ "GenMsgCycleTime" BO_ 1715 1000;
BA_ "GenMsgCycleTime" BO_ 1716 1000;
BA_ "GenMsgCycleTime" BO_ 1717 1000;
BA_ "GenMsgCycleTime" BO_ 1718 1000;
BA_ "GenMsgCycleTime" BO_ 1719 1000;
BA_ "GenMsgCycleTime" BO_ 1720 1000;
